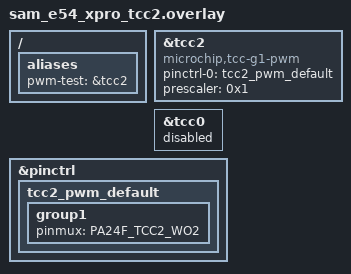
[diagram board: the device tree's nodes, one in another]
/*
 * Copyright (c) 2025 Microchip Technology Inc.
 *
 * SPDX-License-Identifier: Apache-2.0
 */

/ {
	aliases {
		pwm-test = &tcc2;
	};
};

&tcc2 {
	compatible = "microchip,tcc-g1-pwm";
	status = "okay";
	#pwm-cells = < 0x3 >;
	pinctrl-0 = < &tcc2_pwm_default >;
	pinctrl-names = "default";
	prescaler = < 0x1 >;
};

&tcc0 {
	status = "disabled";
};

&pinctrl {
	tcc2_pwm_default: tcc2_pwm_default {
		group1 {
			pinmux = <PA24F_TCC2_WO2>;
		};
	};
};
